# STM32N647 register map
File version: 1.0
CPU: CM55 r0p1, little endian, no MPU, FPU, vendor SysTick, 8 interrupt priority bits
Registers are 32-bit, read-write, reset 0x0 unless marked. A register's access mark holds for its fields unless they carry their own. Offsets are from the block's base; [hi:lo] are bit positions; 'fields as' and 'values as' point back to an identical list.

## DTS — Digital temperature sensor
Base 0x4600A000
Same registers: DTS_S 0x5600A000
0x10 DTS_PVTREG_LOCKR — DTS PVT register lock register
  [31:0] LOCK — PVT software lock register
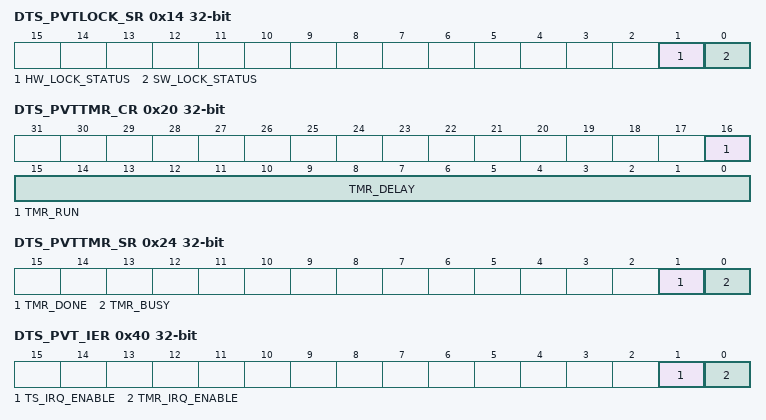
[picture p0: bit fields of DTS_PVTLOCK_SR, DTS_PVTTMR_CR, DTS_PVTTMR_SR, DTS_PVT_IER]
0x14 DTS_PVTLOCK_SR ro — DTS PVT lock status register
  [1] HW_LOCK_STATUS — Hardware lock input status
  [0] SW_LOCK_STATUS — Software lock input status
0x20 DTS_PVTTMR_CR — DTS PVT timer control register
  [16] TMR_RUN — Timer count enable bit
  [15:0] TMR_DELAY — Timer delay
0x24 DTS_PVTTMR_SR ro — DTS PVT timer status register
  [1] TMR_DONE — Counter delay expiration flag
  [0] TMR_BUSY — Counter busy flag
0x40 DTS_PVT_IER — DTS PVT IRQ enable register
  [1] TS_IRQ_ENABLE — TS IRQ source enable bit
  [0] TMR_IRQ_ENABLE — Timer IRQ source enable bit
0x50 DTS_PVTIRQTRMASKR — DTS PVT IRQ timer mask register
  [0] TMR_IRQ_MASK — Timer IRQ source mask bit
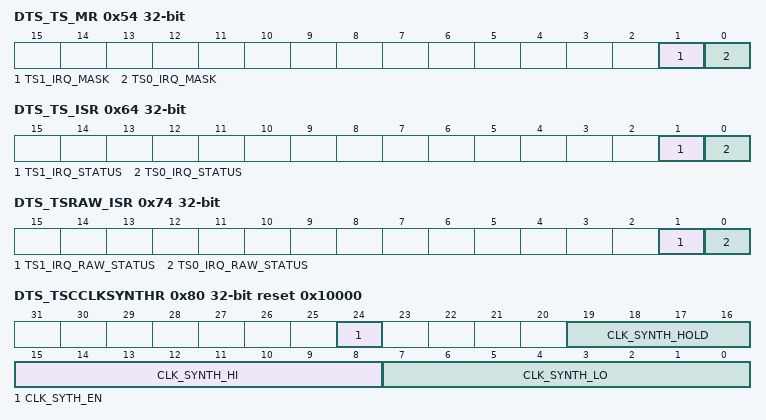
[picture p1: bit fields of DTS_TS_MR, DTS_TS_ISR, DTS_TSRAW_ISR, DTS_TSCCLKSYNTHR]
0x54 DTS_TS_MR — DTS PVT IRQ TS mask register
  [1] TS1_IRQ_MASK — TS1 IRQ source mask bit
  [0] TS0_IRQ_MASK — TS0 IRQ source mask bit
0x60 DTS_PVTTR_SR ro — DTS PVT IRQ timer status register
  [0] TMR_IRQ_STATUS — Timer IRQ status bit after masking
0x64 DTS_TS_ISR ro — DTS PVT IRQ TS status register
  [1] TS1_IRQ_STATUS — TS1 IRQ status bit after masking
  [0] TS0_IRQ_STATUS — TS0 IRQ status bit after masking
0x70 DTS_PVTTMRRAW_ISR ro — DTS PVT IRQ timer raw status register
  [0] TMR_IRQ_RAW_STATUS — TMR IRQ status bit before masking
0x74 DTS_TSRAW_ISR ro — DTS PVT IRQ TS raw status register
  [1] TS1_IRQ_RAW_STATUS — TS1 IRQ status bit before masking
  [0] TS0_IRQ_RAW_STATUS — TS0 IRQ status bit before masking
0x80 DTS_TSCCLKSYNTHR reset 0x10000 — DTS TSC clock synthesizer register
  [24] CLK_SYTH_EN — Synthesized clk_ts enable bit
    0=Disabled; 1=Enabled
  [19:16] CLK_SYNTH_HOLD — SDA master-to-SDA slave output hold delay/SDA slave-to-SDA master input setup delay
  [15:8] CLK_SYNTH_HI — Synthesized clk_ts high period
  [7:0] CLK_SYNTH_LO — Synthesized clk_ts low period
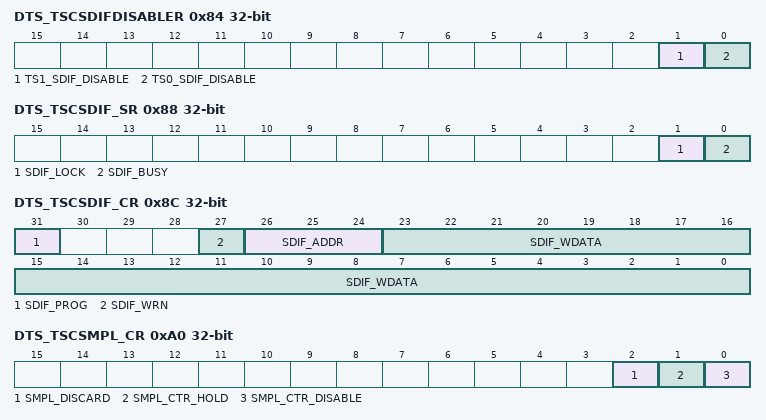
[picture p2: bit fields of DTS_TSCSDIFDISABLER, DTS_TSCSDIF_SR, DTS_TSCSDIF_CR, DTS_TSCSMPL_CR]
0x84 DTS_TSCSDIFDISABLER — DTS TSC SDIF interface disable register
  [1] TS1_SDIF_DISABLE — TS1 serial data interface (SDIF) disable bit
    0=Enabled; 1=Disabled
  [0] TS0_SDIF_DISABLE — TS0 serial data interface (SDIF) disable bit
    0=Enabled; 1=Disabled
0x88 DTS_TSCSDIF_SR ro — DTS TSC SDIF status register
  [1] SDIF_LOCK — SDIF locked flag
    0=Unlocked; 1=Locked
  [0] SDIF_BUSY — SDIF busy flag
    0=SDIF not busy/no clock synthesizer/disable SDIF state update ongoing; 1=SDIF busy/clock synthesizer/disable SDIF state update ongoing
0x8C DTS_TSCSDIF_CR access per field — DTS TSC SDIF register
  [31] SDIF_PROG wo — Serial interface program request
    0=No SDIF program request; 1=SDIF program requested
  [27] SDIF_WRN rw — Serial interface write/no read control bit
    0=SDIF read; 1=SDIF write
  [26:24] SDIF_ADDR rw — Serial interface register address
  [23:0] SDIF_WDATA rw — Serial interface write data
0x90 DTS_TSCSDIFHALTR wo — DTS TSC SDIF halt register
  [0] SDIF_STOP — Serial data interface (SDIF) stop
    0=Not stopped; 1=Stopped
0x94 DTS_TSCSDIF_CFGR — DTS TSC SDIF control register
  [1:0] SDIF_INHIBIT — Serial data interface (SDIF) programming inhibit
    0=No Inhibition; 1=TS0 inhibited/TS1 serial programming activated (SPA); 2=TS1 inhibited/TS0 serial programming activated (SPA); 3=TS1 and TS0 inhibited
0xA0 DTS_TSCSMPL_CR — DTS TSC sample control register
  [2] SMPL_DISCARD — Sample discard bit
    0=Data samples not discarded; 1=Data samples discarded
  [1] SMPL_CTR_HOLD — Sample counter hold bit
    0=Counter not on hold; 1=Counter on hold
  [0] SMPL_CTR_DISABLE — Sample counter disable bit
    0=Sample counter enabled; 1=Sample counter disabled
0xA4 DTS_TSCSDIFSMPLCLRR wo — DTS TSC sample clear register
  [0] SMPL_CNTER_CLEAR — Sample counter clear bit
    0=Counter value not cleared; 1=Counter value cleared
0xA8 DTS_TSCSMPLCNTR ro — DTS TSC sample count register
  [15:0] SMPL_COUNT — Sample counter
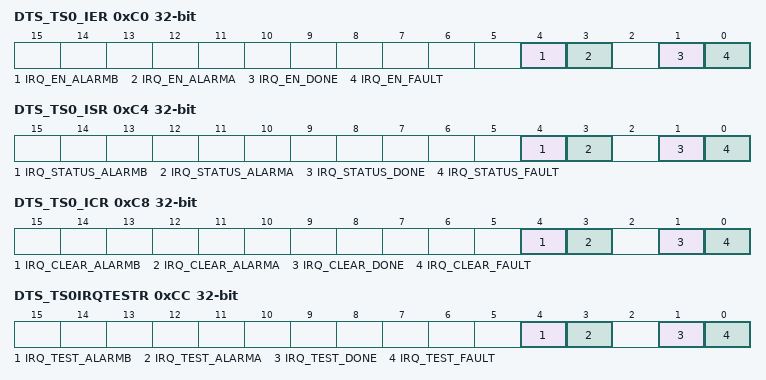
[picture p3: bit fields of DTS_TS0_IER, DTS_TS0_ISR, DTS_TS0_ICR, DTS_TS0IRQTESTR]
0xC0 DTS_TS0_IER — DTS TS0 IRQ enable register
  [4] IRQ_EN_ALARMB — Alarm B IRQ enable bit
  [3] IRQ_EN_ALARMA — Alarm A IRQ enable bit
  [1] IRQ_EN_DONE — Sample done IRQ enable bit
  [0] IRQ_EN_FAULT — Fault IRQ enable bit
0xC4 DTS_TS0_ISR ro — DTS TS0 IRQ status register
  [4] IRQ_STATUS_ALARMB — Alarm B IRQ status bit
  [3] IRQ_STATUS_ALARMA — Alarm A IRQ status bit
  [1] IRQ_STATUS_DONE — Sample done IRQ status bit
  [0] IRQ_STATUS_FAULT — Fault IRQ status bit
0xC8 DTS_TS0_ICR wo — DTS TS0 IRQ clear register
  [4] IRQ_CLEAR_ALARMB — Alarm B IRQ clear bit
  [3] IRQ_CLEAR_ALARMA — Alarm A IRQ clear bit
  [1] IRQ_CLEAR_DONE — Sample done IRQ clear bit
  [0] IRQ_CLEAR_FAULT — Fault IRQ clear bit
0xCC DTS_TS0IRQTESTR — DTS TS0 IRQ test register
  [4] IRQ_TEST_ALARMB — Alarm B IRQ test bit
  [3] IRQ_TEST_ALARMA — Alarm A IRQ test bit
  [1] IRQ_TEST_DONE — Sample done IRQ test bit
  [0] IRQ_TEST_FAULT — Fault IRQ test bit
0xD0 DTS_TS0SDIFRDATAR ro — DTS TS0 SDIF RDATA register
  [23:0] SDIF_RDATA — SDIF read data
0xD4 DTS_TS0SDIFDONER ro — DTS TS0 SDIF done register
  [0] SDIF_SMPL_DONE — Sample done flag
    0=No new data sample available; 1=New data sample available
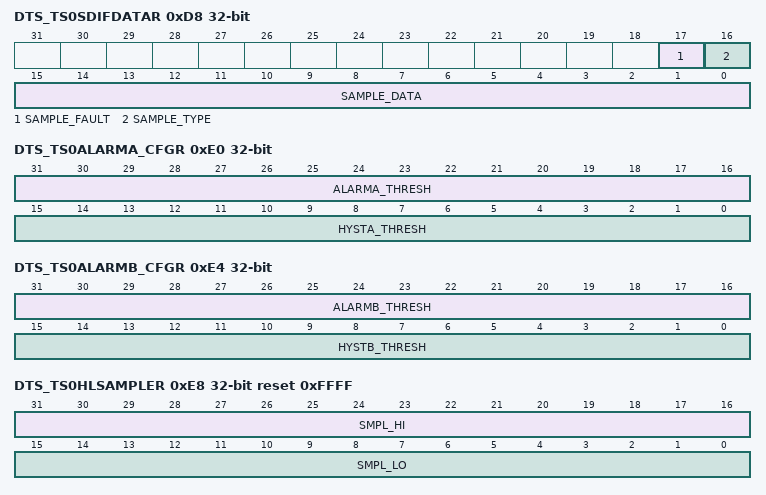
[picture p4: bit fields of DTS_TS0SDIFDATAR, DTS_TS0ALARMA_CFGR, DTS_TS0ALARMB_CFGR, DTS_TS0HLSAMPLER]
0xD8 DTS_TS0SDIFDATAR ro — DTS TS0 SDIF data register
  [17] SAMPLE_FAULT
  [16] SAMPLE_TYPE — TS sample type
    0=Indicates valid data; 1=Indicates either analog access, signature select or fault debug mode
  [15:0] SAMPLE_DATA
0xE0 DTS_TS0ALARMA_CFGR — DTS TS0 alarm A configuration register
  [31:16] ALARMA_THRESH — Alarm A threshold
  [15:0] HYSTA_THRESH — Alarm A hysteresis threshold
0xE4 DTS_TS0ALARMB_CFGR — DTS TS0 alarm B configuration register
  [31:16] ALARMB_THRESH — Alarm B threshold
  [15:0] HYSTB_THRESH — Alarm B hysteresis threshold
0xE8 DTS_TS0HLSAMPLER ro reset 0xFFFF — DTS TS0 high/low sample register
  [31:16] SMPL_HI — Highest valid data sample value received
  [15:0] SMPL_LO — Lowest valid data sample value received
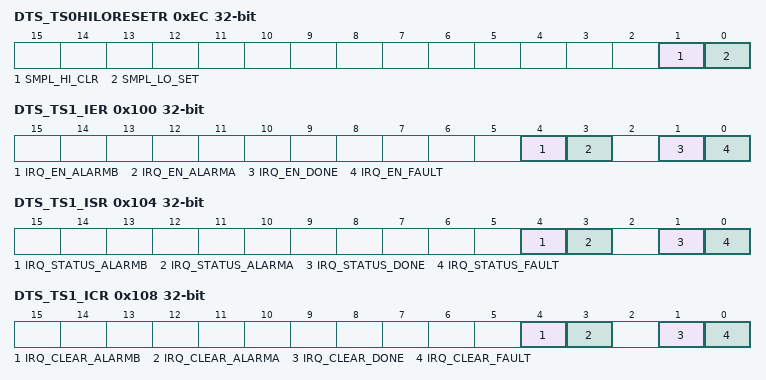
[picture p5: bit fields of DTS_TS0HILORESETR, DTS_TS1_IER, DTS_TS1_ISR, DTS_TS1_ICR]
0xEC DTS_TS0HILORESETR wo — DTS TS0 high/low reset register
  [1] SMPL_HI_CLR — Sample high clear 0
  [0] SMPL_LO_SET — Sample Low Set
0x100 DTS_TS1_IER — DTS TS1 IRQ enable register
  fields as DTS_TS0_IER
0x104 DTS_TS1_ISR ro — DTS TS1 IRQ status register
  fields as DTS_TS0_ISR
0x108 DTS_TS1_ICR wo — DTS TS1 IRQ clear register
  fields as DTS_TS0_ICR
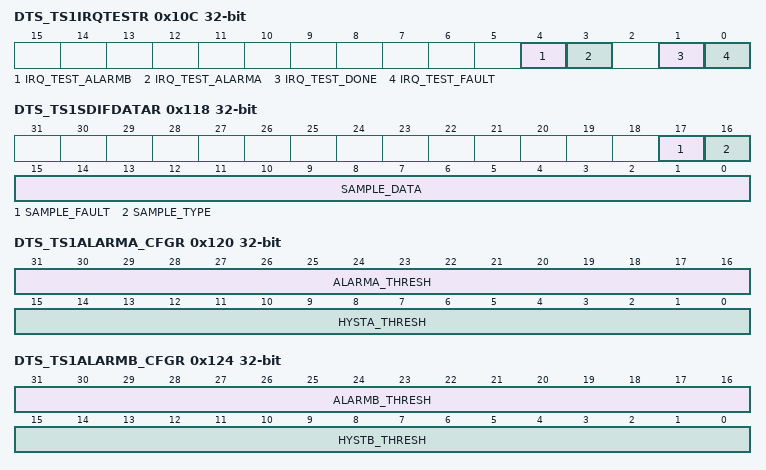
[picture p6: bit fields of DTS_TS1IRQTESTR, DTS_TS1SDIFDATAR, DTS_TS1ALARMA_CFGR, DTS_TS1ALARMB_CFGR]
0x10C DTS_TS1IRQTESTR — DTS TS1 IRQ test register
  fields as DTS_TS0IRQTESTR
0x110 DTS_TS1SDIFRDATAR ro — DTS TS1 SDIF RDATA register
  [23:0] SDIF_RDATA — SDIF read data
0x114 DTS_TS1SDIFDONER ro — DTS TS1 SDIF done register
  fields as DTS_TS0SDIFDONER
0x118 DTS_TS1SDIFDATAR ro — DTS TS1 SDIF data register
  fields as DTS_TS0SDIFDATAR
0x120 DTS_TS1ALARMA_CFGR — DTS TS1 alarm A configuration register
  fields as DTS_TS0ALARMA_CFGR
0x124 DTS_TS1ALARMB_CFGR — DTS TS1 alarm B configuration register
  fields as DTS_TS0ALARMB_CFGR
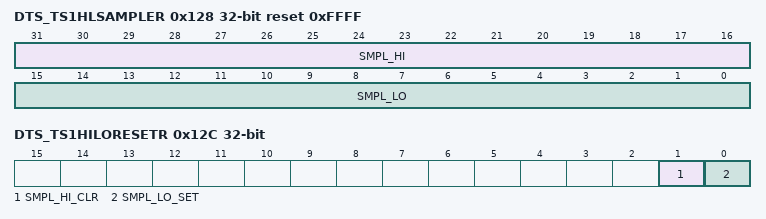
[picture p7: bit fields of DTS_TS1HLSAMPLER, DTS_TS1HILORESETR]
0x128 DTS_TS1HLSAMPLER ro reset 0xFFFF — DTS TS1 high/low sample register
  fields as DTS_TS0HLSAMPLER
0x12C DTS_TS1HILORESETR wo — DTS TS1 high/low reset register
  fields as DTS_TS0HILORESETR
